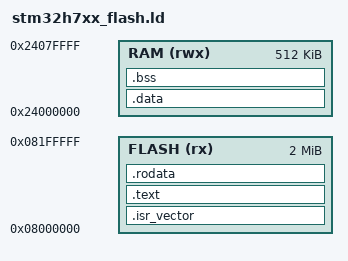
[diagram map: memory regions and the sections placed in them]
/******************************************************************************
 * File:     stm32h7xx_flash.ld
 * Target:   STM32H7xx (Cortex-M7, single-bank flash demo layout)
 * Notice:   Demo stub - STM32H7xx, NOT production.
 *           Used by UC 4.4 overlap check in the CIPHER demo trial.
 *****************************************************************************/

ENTRY(Reset_Handler)

/* End of RAM, used as initial stack top */
_estack = 0x24080000;
_Min_Heap_Size  = 0x200;
_Min_Stack_Size = 0x400;

MEMORY
{
    FLASH (rx)  : ORIGIN = 0x08000000, LENGTH = 2M
    RAM   (rwx) : ORIGIN = 0x24000000, LENGTH = 512K
}

SECTIONS
{
    .isr_vector :
    {
        . = ALIGN(4);
        KEEP(*(.isr_vector))
        . = ALIGN(4);
    } >FLASH

    .text :
    {
        . = ALIGN(4);
        *(.text)
        *(.text*)
        *(.glue_7)
        *(.glue_7t)
        *(.eh_frame)
        . = ALIGN(4);
        _etext = .;
    } >FLASH

    .rodata :
    {
        . = ALIGN(4);
        *(.rodata)
        *(.rodata*)
        . = ALIGN(4);
    } >FLASH

    .data : AT (_etext)
    {
        . = ALIGN(4);
        _sdata = .;
        *(.data)
        *(.data*)
        . = ALIGN(4);
        _edata = .;
    } >RAM

    .bss :
    {
        . = ALIGN(4);
        _sbss = .;
        *(.bss)
        *(.bss*)
        *(COMMON)
        . = ALIGN(4);
        _ebss = .;
    } >RAM
}

/* End of stm32h7xx_flash.ld */
